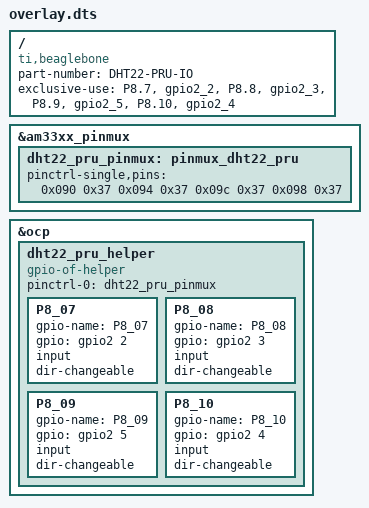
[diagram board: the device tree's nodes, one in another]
/dts-v1/;
/plugin/;

/ {
	compatible = "ti,beaglebone", "ti,beaglebone-black";

	part-number = "DHT22-PRU-IO";

	exclusive-use =
		"P8.7", "gpio2_2",
		"P8.8", "gpio2_3",
		"P8.9", "gpio2_5",
		"P8.10", "gpio2_4";

	fragment@0 {
		target = <&am33xx_pinmux>;
		__overlay__ {
			dht22_pru_pinmux: pinmux_dht22_pru {
				pinctrl-single,pins = <
					0x090 0x37 // P8_07 (TIMER4): mode 7 (gpio), pull up, Rx enabled
					0x094 0x37 // P8_08 (TIMER7): mode 7 (gpio), pull up, Rx enabled
					0x09c 0x37 // P8_09 (TIMER5): mode 7 (gpio), pull up, Rx enabled
					0x098 0x37 // P8_10 (TIMER6): mode 7 (gpio), pull up, Rx enabled
				>;
			};
		};
	};

	fragment@1 {
		target = <&ocp>;
		__overlay__ {
			dht22_pru_helper {
				compatible = "gpio-of-helper";
				pinctrl-names = "default";
				pinctrl-0 = <&dht22_pru_pinmux>;
				status = "okay";

				P8_07 {
					gpio-name = "P8_07";
					gpio = <&gpio2 2 0>;
					input;
					dir-changeable;
				};
				P8_08 {
					gpio-name = "P8_08";
					gpio = <&gpio2 3 0>;
					input;
					dir-changeable;
				};
				P8_09 {
					gpio-name = "P8_09";
					gpio = <&gpio2 5 0>;
					input;
					dir-changeable;
				};
				P8_10 {
					gpio-name = "P8_10";
					gpio = <&gpio2 4 0>;
					input;
					dir-changeable;
				};
			};
		};
	};
};
